# scn_reva register map
Registers are access not given, no defined reset value unless marked. A register's access mark holds for its fields unless they carry their own. Offsets are from the block's base; lines under a group give offsets from that group; [hi:lo] are bit positions; {n}, {i} and the like mark numbered series; 'fields as' and 'values as' point back to an identical list; <NAME> marks a mode.

## Memory map
0x4002C000 SCN size 0x1000 — Smart Card Interface.

## Interrupts
11 SC0 (SCN) — SC0 IRQ

## SCN — Smart Card Interface.
Base 0x4002C000
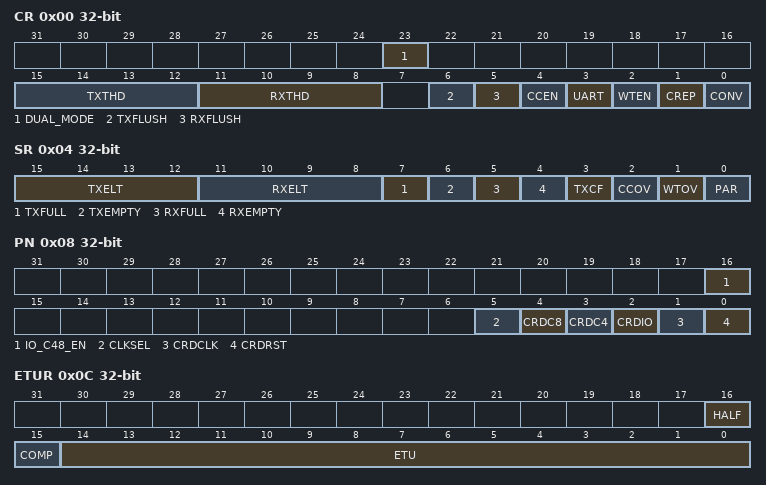
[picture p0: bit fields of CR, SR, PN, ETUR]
0x00 CR — Control Register.
  [23] DUAL_MODE — Dual Internal AFE and Bypass Mode.
  [15:12] TXTHD — Transmit FIFO Depth.
  [11:8] RXTHD — Receive FIFO Depth.
  [6] TXFLUSH — Transmit FIFO Flush.
  [5] RXFLUSH — Receive FIFO Flush.
  [4] CCEN — Clock Counter Enable Bit.
  [3] UART — Smart Card Mode Bit.
  [2] WTEN — Wait Time Counter Enable Bit.
  [1] CREP — Character Repeat Enable Bit.
  [0] CONV — Convention Select Bit.
0x04 SR — Status Register.
  [15:12] TXELT — Number of Bytes in the Transmit FIFO.
  [11:8] RXELT — Number of Bytes in the Receive FIFO.
  [7] TXFULL — Transmit FIFO Full Flag.
  [6] TXEMPTY — Transmit FIFO Empty Flag.
  [5] RXFULL — Receive FIFO Full Flag.
  [4] RXEMPTY — Receive FIFO Empty Flag.
  [3] TXCF — Transmit Complete Flag.
  [2] CCOV — Clock Counter Overflow Flag.
  [1] WTOV — Waiting Time Counter Overflow.
  [0] PAR — Parity Error Detector Flag.
0x08 PN — Pin Register.
  [16] IO_C48_EN — Pin Enable.
  [5] CLKSEL — Smart Card Clock Select.
  [4] CRDC8 — Smart Card SCn_C8 Pin Control.
  [3] CRDC4 — Smart Card SCn_C4 Pin Control.
  [2] CRDIO — Smart Card IO Pin Control.
  [1] CRDCLK — Smart Card Clock Piin Control.
  [0] CRDRST — Smart Card Reset Pin Control.
0x0C ETUR — ETU Register.
  [16] HALF — Half ETU Count Selection Bit.
  [15] COMP — Compensation Mode Enable Bit.
  [14:0] ETU — Elemental Time Unit Value.
0x10 GTR — Guard Time Register.
  [15:0] GT — Guard Time.
0x14 WT0R — Waiting Time 0 Register.
  [31:0] WT — Wait Time.
0x18 WT1R — Waiting Time 1 Register.
  [7:0] WT — Wait Time.
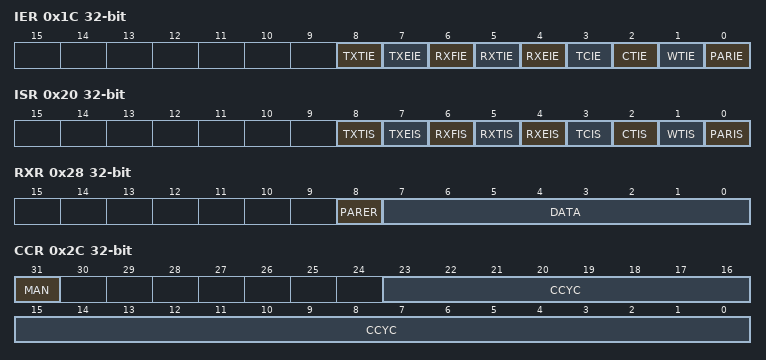
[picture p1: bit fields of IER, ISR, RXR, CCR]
0x1C IER — Interrupt Enable Register.
  [8] TXTIE — Transmit FIFO Threshold Reached Interrupt Enable.
  [7] TXEIE — Transmit FIFO Empty Interrupt Enable.
  [6] RXFIE — Receive FIFO Full Interrupt Enable.
  [5] RXTIE — Receive FIFO Threshold Reached Interrupt Enable.
  [4] RXEIE — Receive FIFO Empty Interrupt Enable.
  [3] TCIE — Character Transmission Completion Interrupt Enable.
  [2] CTIE — Clock Counter Overflow Interrupt Enable.
  [1] WTIE — Waiting Time Overflow Interrupt Enable.
  [0] PARIE — Parity Error Interrupt Enable.
0x20 ISR — Interrupt Status Register.
  [8] TXTIS — Transmit FIFO Threshold Reached Interrupt Status Flag.
  [7] TXEIS — Transmit FIFO Empty Interrupt Status Flag.
  [6] RXFIS — Receive FIFO Full Interrupt Status Flag.
  [5] RXTIS — Receive FIFO Threshold Reached Interrupt Status Flag.
  [4] RXEIS — Receive FIFO Empty Interrupt Status Flag.
  [3] TCIS — Character Transmission Completion Interrupt Status Flag.
  [2] CTIS — Clock Counter Overflow Interrupt Status Flag.
  [1] WTIS — Waiting Time Overflow Interrupt Status Flag.
  [0] PARIS — Parity Error Interrupt Status Flag.
0x24 TXR — Transmit Register.
  [7:0] DATA — Transmit Data.
0x28 RXR — Receive Register.
  [8] PARER — Parity Error Detect Bit.
  [7:0] DATA — Receive Data.
0x2C CCR — Clock Counter Register.
  [31] MAN — Manual Mode.
  [23:0] CCYC — Number of Clock Cycles to Count.
